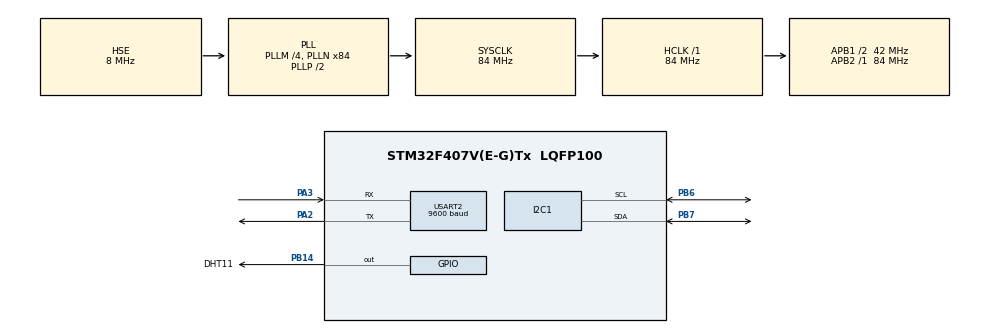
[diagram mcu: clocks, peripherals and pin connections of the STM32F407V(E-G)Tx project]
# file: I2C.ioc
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Mcu.Family=STM32F4
Mcu.Name=STM32F407V(E-G)Tx
Mcu.Package=LQFP100
NVIC.PriorityGroup=NVIC_PRIORITYGROUP_4
NVIC.USART2_IRQn=true\:0\:0\:false\:false\:true\:true\:true
PA13.Mode=Serial_Wire
PA13.Signal=SYS_JTMS-SWDIO
PA14.Mode=Serial_Wire
PA14.Signal=SYS_JTCK-SWCLK
PA2.Mode=Asynchronous
PA2.Signal=USART2_TX
PA3.Mode=Asynchronous
PA3.Signal=USART2_RX
PB14.GPIO_Label=DHT11
PB14.Signal=GPIO_Output
PB6.Mode=I2C
PB6.Signal=I2C1_SCL
PB7.Mode=I2C
PB7.Signal=I2C1_SDA
PH0-OSC_IN.Mode=HSE-External-Oscillator
PH0-OSC_IN.Signal=RCC_OSC_IN
PH1-OSC_OUT.Mode=HSE-External-Oscillator
PH1-OSC_OUT.Signal=RCC_OSC_OUT
ProjectManager.HeapSize=0x200
ProjectManager.StackSize=0x400
ProjectManager.TargetToolchain=MDK-ARM V5.32
RCC.48MHZClocksFreq_Value=42000000
RCC.AHBFreq_Value=84000000
RCC.APB1CLKDivider=RCC_HCLK_DIV2
RCC.APB1Freq_Value=42000000
RCC.APB1TimFreq_Value=84000000
RCC.APB2Freq_Value=84000000
RCC.APB2TimFreq_Value=84000000
RCC.CortexFreq_Value=84000000
RCC.HCLKFreq_Value=84000000
RCC.HSE_VALUE=8000000
RCC.HSI_VALUE=16000000
RCC.LSE_VALUE=32768
RCC.PLLM=4
RCC.PLLN=84
RCC.PLLSourceVirtual=RCC_PLLSOURCE_HSE
RCC.SYSCLKFreq_VALUE=84000000
RCC.SYSCLKSource=RCC_SYSCLKSOURCE_PLLCLK
RCC.VCOOutputFreq_Value=168000000
TIM4.Period=0xFFFF-1
TIM4.Prescaler=84-1
USART2.BaudRate=9600
USART2.VirtualMode=VM_ASYNC
VP_TIM4_VS_ClockSourceINT.Mode=Internal
board=custom

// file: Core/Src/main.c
/* USER CODE BEGIN Header */
/**
  ******************************************************************************
  * @file           : main.c
  * @brief          : Main program body
  ******************************************************************************
  * @attention
  *
  * Copyright (c) 2022 STMicroelectronics.
  * All rights reserved.
  *
  * This software is licensed under terms that can be found in the LICENSE file
  * in the root directory of this software component.
  * If no LICENSE file comes with this software, it is provided AS-IS.
  *
  ******************************************************************************
  */
/* USER CODE END Header */
#include "main.h"
#include "DHT.h"
#include <stdbool.h>
#include <stdint.h>
#include <string.h>
#include <math.h>
#include <stdio.h>
#include <stdlib.h>

I2C_HandleTypeDef hi2c1;

TIM_HandleTypeDef htim4;

UART_HandleTypeDef huart2;

/* USER CODE BEGIN PV */
DHT_Name DHT1;
/* USER CODE END PV */

void SystemClock_Config(void);
static void MX_GPIO_Init(void);
static void MX_I2C1_Init(void);
static void MX_USART2_UART_Init(void);
static void MX_TIM4_Init(void);
/* USER CODE BEGIN PFP */
uint8_t nRxData[7];
uint8_t g_strCommand[4];
/* USER CODE END PFP */

int main(void)
{

  /* MCU Configuration--------------------------------------------------------*/

  /* Reset of all peripherals, Initializes the Flash interface and the Systick. */
  HAL_Init();

  /* Configure the system clock */
  SystemClock_Config();

  /* Initialize all configured peripherals */
  MX_GPIO_Init();
  MX_I2C1_Init();
  MX_USART2_UART_Init();
  MX_TIM4_Init();
  /* USER CODE BEGIN 2 */
	DHT_Init(&DHT1,DHT11,&htim4,DHT11_GPIO_Port, DHT11_Pin);
	HAL_UART_Receive_IT(&huart2, (uint8_t *)nRxData, 7);
  /* USER CODE END 2 */

  /* Infinite loop */
  while (1)
  {

    /* USER CODE BEGIN 3 */
		DHT_ReadTempHum(&DHT1);
		HAL_Delay(1000);
  }
  /* USER CODE END 3 */
}
uint8_t *subString(uint8_t *s, int pos, int index)
{
	uint8_t *t = &s[pos];
	s[pos-1]= '\0';
	for (int i = index; i < (strlen((char *)t) + 1);i++)
	{
		t[i] ='\0';
	}
	return t;
}
bool StrCompare(uint8_t *pBuff, uint8_t *Sample, uint8_t nSize)
{
	for (int i = 0; i < nSize; i++)
	{
		if(pBuff[i] != Sample[i])
		{
			return false;
		}
	}
	return true;
}
void HAL_UART_RxCpltCallback(UART_HandleTypeDef *huart)
{
	if(huart->Instance == USART2)
	{
		HAL_UART_Receive_IT(&huart2, (uint8_t *)nRxData, 7);
		memcpy(g_strCommand,subString(nRxData, 1, 4),4);
		memset(nRxData, 0, sizeof(nRxData));
		if (StrCompare(g_strCommand, (uint8_t *)"Temp", 4))
		{
			HAL_UART_Transmit(&huart2,(uint8_t *)DHT1.Temp, 7, 1000);
		}
		else if (StrCompare(g_strCommand, (uint8_t *)"Humi", 4))
		{
			HAL_UART_Transmit(&huart2,(uint8_t *)DHT1.Humi, 6, 1000);
		}
	}
}
void SystemClock_Config(void)
{
  RCC_OscInitTypeDef RCC_OscInitStruct = {0};
  RCC_ClkInitTypeDef RCC_ClkInitStruct = {0};

  /** Configure the main internal regulator output voltage
  */
  __HAL_RCC_PWR_CLK_ENABLE();
  __HAL_PWR_VOLTAGESCALING_CONFIG(PWR_REGULATOR_VOLTAGE_SCALE1);
  /** Initializes the RCC Oscillators according to the specified parameters
  * in the RCC_OscInitTypeDef structure.
  */
  RCC_OscInitStruct.OscillatorType = RCC_OSCILLATORTYPE_HSE;
  RCC_OscInitStruct.HSEState = RCC_HSE_ON;
  RCC_OscInitStruct.PLL.PLLState = RCC_PLL_ON;
  RCC_OscInitStruct.PLL.PLLSource = RCC_PLLSOURCE_HSE;
  RCC_OscInitStruct.PLL.PLLM = 4;
  RCC_OscInitStruct.PLL.PLLN = 84;
  RCC_OscInitStruct.PLL.PLLP = RCC_PLLP_DIV2;
  RCC_OscInitStruct.PLL.PLLQ = 4;
  if (HAL_RCC_OscConfig(&RCC_OscInitStruct) != HAL_OK)
  {
    Error_Handler();
  }
  /** Initializes the CPU, AHB and APB buses clocks
  */
  RCC_ClkInitStruct.ClockType = RCC_CLOCKTYPE_HCLK|RCC_CLOCKTYPE_SYSCLK
                              |RCC_CLOCKTYPE_PCLK1|RCC_CLOCKTYPE_PCLK2;
  RCC_ClkInitStruct.SYSCLKSource = RCC_SYSCLKSOURCE_PLLCLK;
  RCC_ClkInitStruct.AHBCLKDivider = RCC_SYSCLK_DIV1;
  RCC_ClkInitStruct.APB1CLKDivider = RCC_HCLK_DIV2;
  RCC_ClkInitStruct.APB2CLKDivider = RCC_HCLK_DIV1;

  if (HAL_RCC_ClockConfig(&RCC_ClkInitStruct, FLASH_LATENCY_2) != HAL_OK)
  {
    Error_Handler();
  }
}

static void MX_I2C1_Init(void)
{

  hi2c1.Instance = I2C1;
  hi2c1.Init.ClockSpeed = 100000;
  hi2c1.Init.DutyCycle = I2C_DUTYCYCLE_2;
  hi2c1.Init.OwnAddress1 = 0;
  hi2c1.Init.AddressingMode = I2C_ADDRESSINGMODE_7BIT;
  hi2c1.Init.DualAddressMode = I2C_DUALADDRESS_DISABLE;
  hi2c1.Init.OwnAddress2 = 0;
  hi2c1.Init.GeneralCallMode = I2C_GENERALCALL_DISABLE;
  hi2c1.Init.NoStretchMode = I2C_NOSTRETCH_DISABLE;
  if (HAL_I2C_Init(&hi2c1) != HAL_OK)
  {
    Error_Handler();
  }

}

static void MX_TIM4_Init(void)
{

  TIM_ClockConfigTypeDef sClockSourceConfig = {0};
  TIM_MasterConfigTypeDef sMasterConfig = {0};

  htim4.Instance = TIM4;
  htim4.Init.Prescaler = 84-1;
  htim4.Init.CounterMode = TIM_COUNTERMODE_UP;
  htim4.Init.Period = 0xFFFF-1;
  htim4.Init.ClockDivision = TIM_CLOCKDIVISION_DIV1;
  htim4.Init.AutoReloadPreload = TIM_AUTORELOAD_PRELOAD_DISABLE;
  if (HAL_TIM_Base_Init(&htim4) != HAL_OK)
  {
    Error_Handler();
  }
  sClockSourceConfig.ClockSource = TIM_CLOCKSOURCE_INTERNAL;
  if (HAL_TIM_ConfigClockSource(&htim4, &sClockSourceConfig) != HAL_OK)
  {
    Error_Handler();
  }
  sMasterConfig.MasterOutputTrigger = TIM_TRGO_RESET;
  sMasterConfig.MasterSlaveMode = TIM_MASTERSLAVEMODE_DISABLE;
  if (HAL_TIMEx_MasterConfigSynchronization(&htim4, &sMasterConfig) != HAL_OK)
  {
    Error_Handler();
  }

}

static void MX_USART2_UART_Init(void)
{

  huart2.Instance = USART2;
  huart2.Init.BaudRate = 9600;
  huart2.Init.WordLength = UART_WORDLENGTH_8B;
  huart2.Init.StopBits = UART_STOPBITS_1;
  huart2.Init.Parity = UART_PARITY_NONE;
  huart2.Init.Mode = UART_MODE_TX_RX;
  huart2.Init.HwFlowCtl = UART_HWCONTROL_NONE;
  huart2.Init.OverSampling = UART_OVERSAMPLING_16;
  if (HAL_UART_Init(&huart2) != HAL_OK)
  {
    Error_Handler();
  }

}

static void MX_GPIO_Init(void)
{
  GPIO_InitTypeDef GPIO_InitStruct = {0};

  /* GPIO Ports Clock Enable */
  __HAL_RCC_GPIOH_CLK_ENABLE();
  __HAL_RCC_GPIOA_CLK_ENABLE();
  __HAL_RCC_GPIOB_CLK_ENABLE();

  /*Configure GPIO pin Output Level */
  HAL_GPIO_WritePin(DHT11_GPIO_Port, DHT11_Pin, GPIO_PIN_RESET);

  /*Configure GPIO pin : DHT11_Pin */
  GPIO_InitStruct.Pin = DHT11_Pin;
  GPIO_InitStruct.Mode = GPIO_MODE_OUTPUT_PP;
  GPIO_InitStruct.Pull = GPIO_NOPULL;
  GPIO_InitStruct.Speed = GPIO_SPEED_FREQ_LOW;
  HAL_GPIO_Init(DHT11_GPIO_Port, &GPIO_InitStruct);

}

void Error_Handler(void)
{
  __disable_irq();
  while (1)
  {
  }
}
